# PIC32MK0512GPG064 register map
Vendor: Microchip
Registers are 32-bit, read-write, reset 0x0 unless marked. A register's access mark holds for its fields unless they carry their own. Addresses are absolute, and some are shared; only a register's first bit layout is shown; [hi:lo] are bit positions; {n}, {i} and the like mark numbered series.

## PORTC
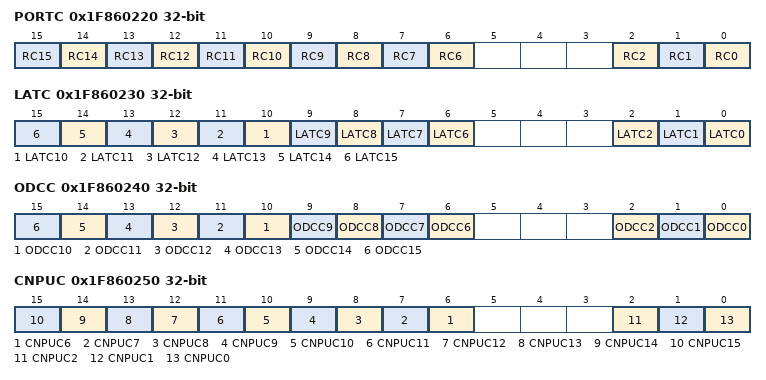
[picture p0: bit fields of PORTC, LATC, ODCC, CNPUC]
0x1F860220 PORTC reset not defined — (power-on value ----------------xxxxxxxxxx---xxx)
  [n] RC{n} (n=6..15), [2] RC2, [1] RC1, [0] RC0
0x1F860230 LATC reset not defined — (power-on value ----------------xxxxxxxxxx---xxx)
  [n] LATC{n} (n=6..15), [2] LATC2, [1] LATC1, [0] LATC0
0x1F860240 ODCC
  [n] ODCC{n} (n=6..15), [2] ODCC2, [1] ODCC1, [0] ODCC0
0x1F860250 CNPUC
  [n] CNPUC{n} (n=6..15), [2] CNPUC2, [1] CNPUC1, [0] CNPUC0
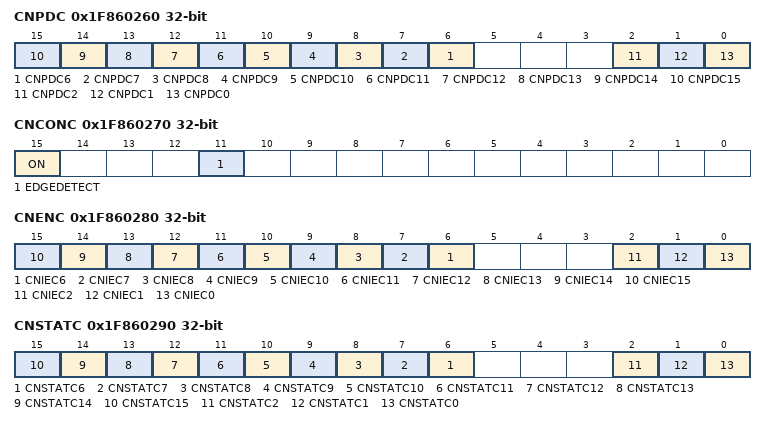
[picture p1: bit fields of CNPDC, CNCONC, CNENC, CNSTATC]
0x1F860260 CNPDC
  [n] CNPDC{n} (n=6..15), [2] CNPDC2, [1] CNPDC1, [0] CNPDC0
0x1F860270 CNCONC
  [15] ON, [11] EDGEDETECT
0x1F860280 CNENC
  [n] CNIEC{n} (n=6..15), [2] CNIEC2, [1] CNIEC1, [0] CNIEC0
0x1F860290 CNSTATC
  [n] CNSTATC{n} (n=6..15), [2] CNSTATC2, [1] CNSTATC1, [0] CNSTATC0
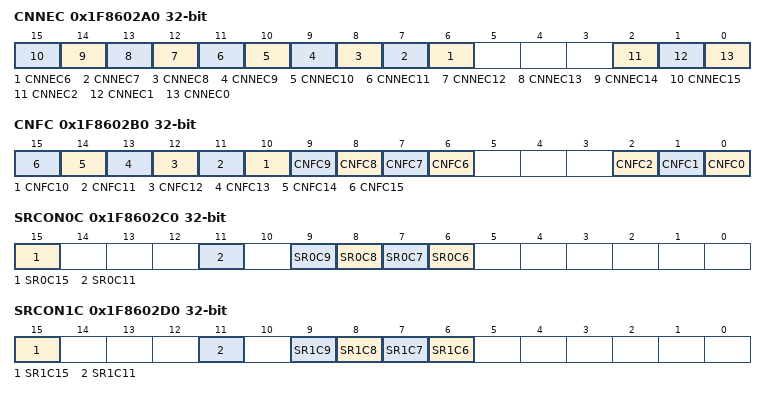
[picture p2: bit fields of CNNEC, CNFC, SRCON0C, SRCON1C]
0x1F8602A0 CNNEC
  [n] CNNEC{n} (n=6..15), [2] CNNEC2, [1] CNNEC1, [0] CNNEC0
0x1F8602B0 CNFC
  [n] CNFC{n} (n=6..15), [2] CNFC2, [1] CNFC1, [0] CNFC0
0x1F8602C0 SRCON0C
  [15] SR0C15, [11] SR0C11, [n] SR0C{n} (n=6..9)
0x1F8602D0 SRCON1C
  [15] SR1C15, [11] SR1C11, [n] SR1C{n} (n=6..9)

## PORTD
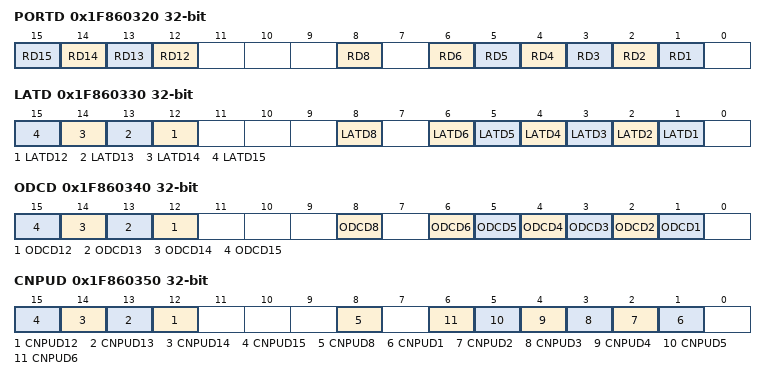
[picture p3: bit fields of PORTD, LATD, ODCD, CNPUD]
0x1F860320 PORTD reset not defined — (power-on value ----------------xxxx---x-xxxxxx-)
  [n] RD{n} (n=12..15), [8] RD8, [n] RD{n} (n=1..6)
0x1F860330 LATD reset not defined — (power-on value ----------------xxxx---x-xxxxxx-)
  [n] LATD{n} (n=12..15), [8] LATD8, [n] LATD{n} (n=1..6)
0x1F860340 ODCD
  [n] ODCD{n} (n=12..15), [8] ODCD8, [n] ODCD{n} (n=1..6)
0x1F860350 CNPUD
  [n] CNPUD{n} (n=12..15), [8] CNPUD8, [n] CNPUD{n} (n=1..6)
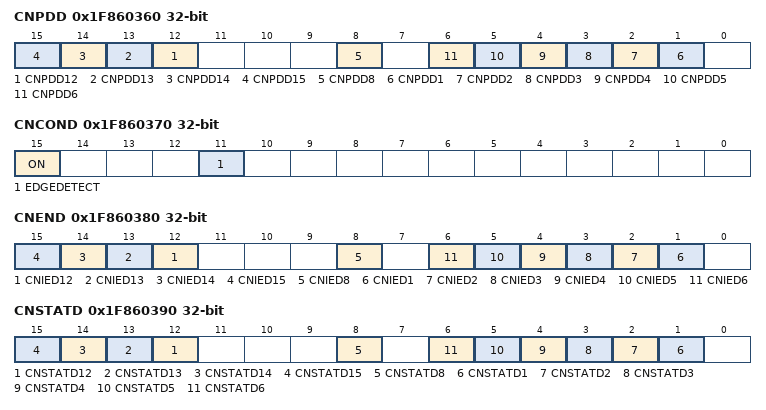
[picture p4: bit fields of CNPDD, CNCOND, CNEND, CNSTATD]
0x1F860360 CNPDD
  [n] CNPDD{n} (n=12..15), [8] CNPDD8, [n] CNPDD{n} (n=1..6)
0x1F860370 CNCOND
  [15] ON, [11] EDGEDETECT
0x1F860380 CNEND
  [n] CNIED{n} (n=12..15), [8] CNIED8, [n] CNIED{n} (n=1..6)
0x1F860390 CNSTATD
  [n] CNSTATD{n} (n=12..15), [8] CNSTATD8, [n] CNSTATD{n} (n=1..6)
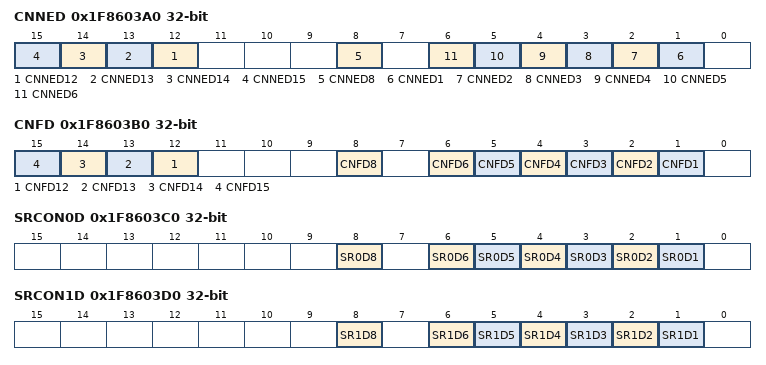
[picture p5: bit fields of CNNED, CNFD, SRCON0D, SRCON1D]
0x1F8603A0 CNNED
  [n] CNNED{n} (n=12..15), [8] CNNED8, [n] CNNED{n} (n=1..6)
0x1F8603B0 CNFD
  [n] CNFD{n} (n=12..15), [8] CNFD8, [n] CNFD{n} (n=1..6)
0x1F8603C0 SRCON0D
  [8] SR0D8, [n] SR0D{n} (n=1..6)
0x1F8603D0 SRCON1D
  [8] SR1D8, [n] SR1D{n} (n=1..6)

## PORTE
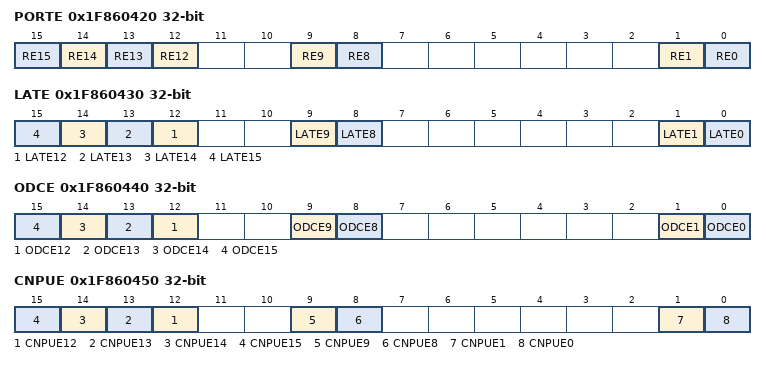
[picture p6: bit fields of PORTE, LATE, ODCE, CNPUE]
0x1F860420 PORTE reset not defined — (power-on value ----------------xxxx--xx------xx)
  [n] RE{n} (n=12..15), [9] RE9, [8] RE8, [1] RE1, [0] RE0
0x1F860430 LATE reset not defined — (power-on value ----------------xxxx--xx------xx)
  [n] LATE{n} (n=12..15), [9] LATE9, [8] LATE8, [1] LATE1, [0] LATE0
0x1F860440 ODCE
  [n] ODCE{n} (n=12..15), [9] ODCE9, [8] ODCE8, [1] ODCE1, [0] ODCE0
0x1F860450 CNPUE
  [n] CNPUE{n} (n=12..15), [9] CNPUE9, [8] CNPUE8, [1] CNPUE1, [0] CNPUE0
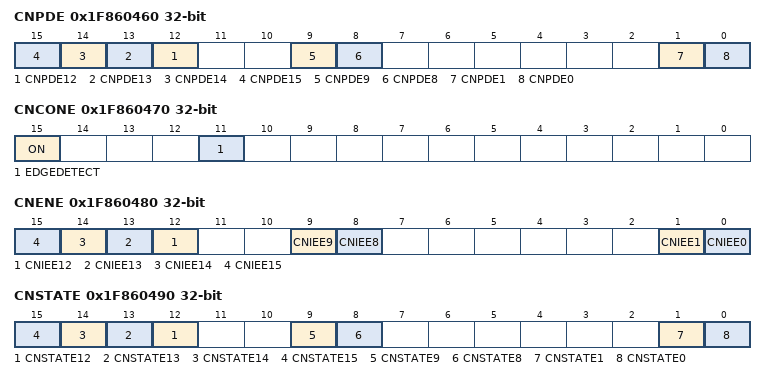
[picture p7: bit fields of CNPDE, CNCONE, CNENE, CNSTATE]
0x1F860460 CNPDE
  [n] CNPDE{n} (n=12..15), [9] CNPDE9, [8] CNPDE8, [1] CNPDE1, [0] CNPDE0
0x1F860470 CNCONE
  [15] ON, [11] EDGEDETECT
0x1F860480 CNENE
  [n] CNIEE{n} (n=12..15), [9] CNIEE9, [8] CNIEE8, [1] CNIEE1, [0] CNIEE0
0x1F860490 CNSTATE
  [n] CNSTATE{n} (n=12..15), [9] CNSTATE9, [8] CNSTATE8, [1] CNSTATE1, [0] CNSTATE0
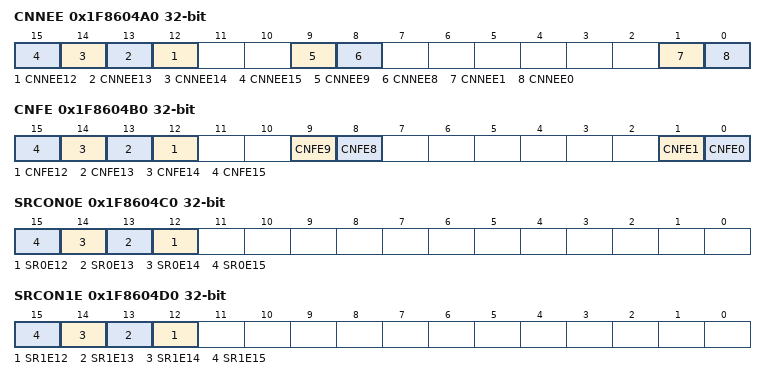
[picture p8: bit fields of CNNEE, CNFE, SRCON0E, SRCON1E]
0x1F8604A0 CNNEE
  [n] CNNEE{n} (n=12..15), [9] CNNEE9, [8] CNNEE8, [1] CNNEE1, [0] CNNEE0
0x1F8604B0 CNFE
  [n] CNFE{n} (n=12..15), [9] CNFE9, [8] CNFE8, [1] CNFE1, [0] CNFE0
0x1F8604C0 SRCON0E
  [n] SR0E{n} (n=12..15)
0x1F8604D0 SRCON1E
  [n] SR1E{n} (n=12..15)

## PORTF
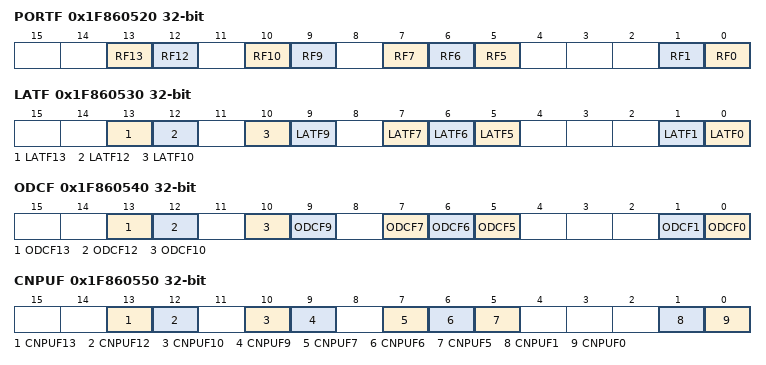
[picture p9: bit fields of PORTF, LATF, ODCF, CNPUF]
0x1F860520 PORTF reset not defined — (power-on value ------------------xx-xx-xxx---xx)
  [13] RF13, [12] RF12, [10] RF10, [9] RF9, [7] RF7, [6] RF6, [5] RF5, [1] RF1, [0] RF0
0x1F860530 LATF reset not defined — (power-on value ------------------xx-xx-xxx---xx)
  [13] LATF13, [12] LATF12, [10] LATF10, [9] LATF9, [7] LATF7, [6] LATF6, [5] LATF5, [1] LATF1, [0] LATF0
0x1F860540 ODCF
  [13] ODCF13, [12] ODCF12, [10] ODCF10, [9] ODCF9, [7] ODCF7, [6] ODCF6, [5] ODCF5, [1] ODCF1, [0] ODCF0
0x1F860550 CNPUF
  [13] CNPUF13, [12] CNPUF12, [10] CNPUF10, [9] CNPUF9, [7] CNPUF7, [6] CNPUF6, [5] CNPUF5, [1] CNPUF1, [0] CNPUF0
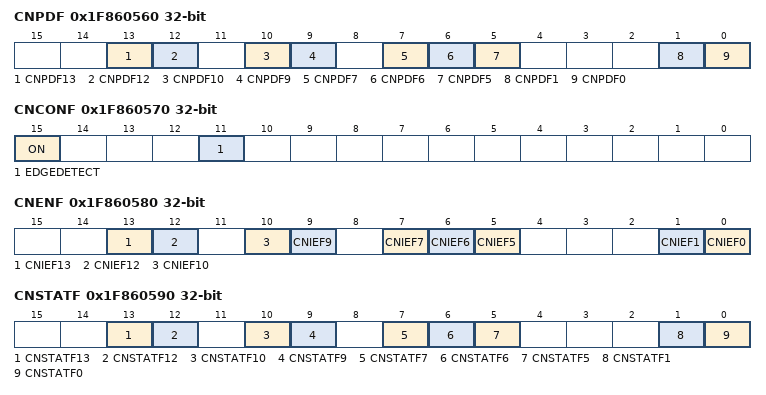
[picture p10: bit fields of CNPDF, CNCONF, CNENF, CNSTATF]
0x1F860560 CNPDF
  [13] CNPDF13, [12] CNPDF12, [10] CNPDF10, [9] CNPDF9, [7] CNPDF7, [6] CNPDF6, [5] CNPDF5, [1] CNPDF1, [0] CNPDF0
0x1F860570 CNCONF
  [15] ON, [11] EDGEDETECT
0x1F860580 CNENF
  [13] CNIEF13, [12] CNIEF12, [10] CNIEF10, [9] CNIEF9, [7] CNIEF7, [6] CNIEF6, [5] CNIEF5, [1] CNIEF1, [0] CNIEF0
0x1F860590 CNSTATF
  [13] CNSTATF13, [12] CNSTATF12, [10] CNSTATF10, [9] CNSTATF9, [7] CNSTATF7, [6] CNSTATF6, [5] CNSTATF5, [1] CNSTATF1, [0] CNSTATF0
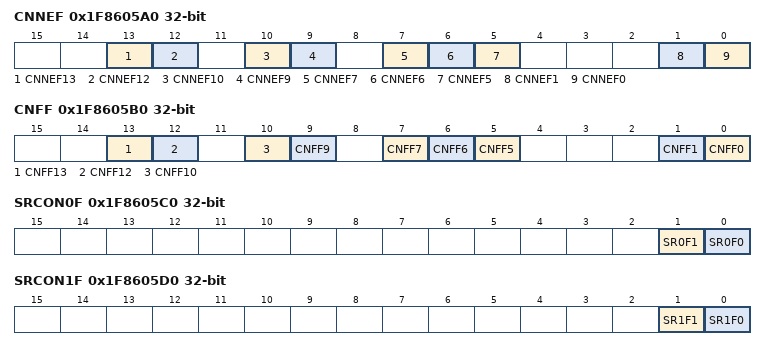
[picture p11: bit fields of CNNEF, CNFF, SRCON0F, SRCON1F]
0x1F8605A0 CNNEF
  [13] CNNEF13, [12] CNNEF12, [10] CNNEF10, [9] CNNEF9, [7] CNNEF7, [6] CNNEF6, [5] CNNEF5, [1] CNNEF1, [0] CNNEF0
0x1F8605B0 CNFF
  [13] CNFF13, [12] CNFF12, [10] CNFF10, [9] CNFF9, [7] CNFF7, [6] CNFF6, [5] CNFF5, [1] CNFF1, [0] CNFF0
0x1F8605C0 SRCON0F
  [1] SR0F1, [0] SR0F0
0x1F8605D0 SRCON1F
  [1] SR1F1, [0] SR1F0
